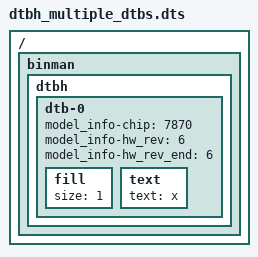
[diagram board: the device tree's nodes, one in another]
// SPDX-License-Identifier: GPL-2.0+

/dts-v1/;

/ {
	binman {
		dtbh {
			dtb-0 {
				model_info-chip = <7870>;
				model_info-hw_rev = <6>;
				model_info-hw_rev_end = <6>;

				fill {
					size = <1>;
				};
				text {
					text = "x";
				};
			};
		};
	};
};
